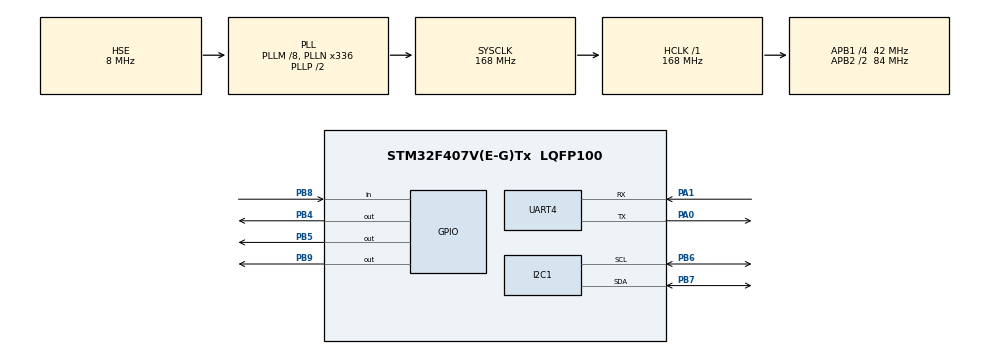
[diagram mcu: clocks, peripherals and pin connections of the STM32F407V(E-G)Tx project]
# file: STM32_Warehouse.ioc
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Dma.Request0=UART4_TX
Dma.UART4_TX.0.Direction=DMA_MEMORY_TO_PERIPH
Dma.UART4_TX.0.FIFOMode=DMA_FIFOMODE_DISABLE
Dma.UART4_TX.0.Instance=DMA1_Stream4
Dma.UART4_TX.0.MemDataAlignment=DMA_MDATAALIGN_BYTE
Dma.UART4_TX.0.MemInc=DMA_MINC_ENABLE
Dma.UART4_TX.0.Mode=DMA_NORMAL
Dma.UART4_TX.0.PeriphDataAlignment=DMA_PDATAALIGN_BYTE
Dma.UART4_TX.0.PeriphInc=DMA_PINC_DISABLE
Dma.UART4_TX.0.Priority=DMA_PRIORITY_HIGH
FREERTOS.Tasks01=defaultTask,0,128,StartDefaultTask,Default,NULL,Dynamic,NULL,NULL;myTask02,0,256,StartTask02,Default,NULL,Dynamic,NULL,NULL;myTask03,-1,128,StartTask03,Default,NULL,Dynamic,NULL,NULL
FREERTOS.configUSE_TIMERS=0
I2C1.I2C_Mode=I2C_Fast
Mcu.Family=STM32F4
Mcu.Name=STM32F407V(E-G)Tx
Mcu.Package=LQFP100
NVIC.DMA1_Stream4_IRQn=true\:5\:0\:false\:false\:true\:true\:false\:true\:true
NVIC.PriorityGroup=NVIC_PRIORITYGROUP_4
NVIC.TIM1_UP_TIM10_IRQn=true\:0\:0\:true\:false\:true\:false\:false\:true\:true
NVIC.TimeBase=TIM1_UP_TIM10_IRQn
NVIC.TimeBaseIP=TIM1
PA0-WKUP.Mode=Asynchronous
PA0-WKUP.Signal=UART4_TX
PA1.Mode=Asynchronous
PA1.Signal=UART4_RX
PA13.Mode=Serial_Wire
PA13.Signal=SYS_JTMS-SWDIO
PA14.Mode=Serial_Wire
PA14.Signal=SYS_JTCK-SWCLK
PB4.GPIO_PuPd=GPIO_PULLDOWN
PB4.PinState=GPIO_PIN_RESET
PB4.Signal=GPIO_Output
PB5.GPIO_PuPd=GPIO_PULLDOWN
PB5.PinState=GPIO_PIN_RESET
PB5.Signal=GPIO_Output
PB6.Mode=I2C
PB6.Signal=I2C1_SCL
PB7.Mode=I2C
PB7.Signal=I2C1_SDA
PB8.GPIO_Mode=GPIO_MODE_INPUT
PB8.GPIO_PuPd=GPIO_PULLDOWN
PB8.Signal=GPIO_Input
PB9.PinState=GPIO_PIN_RESET
PB9.Signal=GPIO_Output
PH0-OSC_IN.Mode=HSE-External-Oscillator
PH0-OSC_IN.Signal=RCC_OSC_IN
PH1-OSC_OUT.Mode=HSE-External-Oscillator
PH1-OSC_OUT.Signal=RCC_OSC_OUT
ProjectManager.HeapSize=0x1000
ProjectManager.StackSize=0x1000
ProjectManager.TargetToolchain=CMake
RCC.48MHZClocksFreq_Value=84000000
RCC.AHBFreq_Value=168000000
RCC.APB1CLKDivider=RCC_HCLK_DIV4
RCC.APB1Freq_Value=42000000
RCC.APB1TimFreq_Value=84000000
RCC.APB2CLKDivider=RCC_HCLK_DIV2
RCC.APB2Freq_Value=84000000
RCC.APB2TimFreq_Value=168000000
RCC.CortexFreq_Value=168000000
RCC.HCLKFreq_Value=168000000
RCC.HSE_VALUE=8000000
RCC.HSI_VALUE=16000000
RCC.LSE_VALUE=32768
RCC.PLLM=8
RCC.PLLN=336
RCC.PLLSourceVirtual=RCC_PLLSOURCE_HSE
RCC.SYSCLKFreq_VALUE=168000000
RCC.SYSCLKSource=RCC_SYSCLKSOURCE_PLLCLK
RCC.VCOOutputFreq_Value=336000000
UART4.VirtualMode=Asynchronous
VP_FREERTOS_VS_CMSIS_V1.Mode=CMSIS_V1
VP_SYS_VS_tim1.Mode=TIM1
board=custom

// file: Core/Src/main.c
/* USER CODE BEGIN Header */
/**
 ******************************************************************************
 * @file           : main.c
 * @brief          : Main program body
 ******************************************************************************
 * @attention
 *
 * Copyright (c) 2024 STMicroelectronics.
 * All rights reserved.
 *
 * This software is licensed under terms that can be found in the LICENSE file
 * in the root directory of this software component.
 * If no LICENSE file comes with this software, it is provided AS-IS.
 *
 ******************************************************************************
 */
/* USER CODE END Header */
#include "main.h"
#include "cmsis_os.h"
#include "dma.h"
#include "i2c.h"
#include "usart.h"
#include "gpio.h"

void SystemClock_Config(void);
void MX_FREERTOS_Init(void);

int main(void)
{

  /* MCU Configuration--------------------------------------------------------*/

  /* Reset of all peripherals, Initializes the Flash interface and the Systick. */
  HAL_Init();

  /* Configure the system clock */
  SystemClock_Config();

  /* Initialize all configured peripherals */
  MX_GPIO_Init();
  MX_DMA_Init();
  MX_I2C1_Init();
  MX_UART4_Init();
  /* USER CODE BEGIN 2 */
  USART1_Init(115200);
  USART2_Init(115200);
  USART3_Init(115200);
  UART4_Init(115200);
  USART6_Init(115200);
  /* USER CODE END 2 */

  /* Call init function for freertos objects (in cmsis_os2.c) */
  MX_FREERTOS_Init();

  /* Start scheduler */
  osKernelStart();

  /* We should never get here as control is now taken by the scheduler */

  /* Infinite loop */
    while (1) {

    }
}

void SystemClock_Config(void)
{
  RCC_OscInitTypeDef RCC_OscInitStruct = {0};
  RCC_ClkInitTypeDef RCC_ClkInitStruct = {0};

  /** Configure the main internal regulator output voltage
  */
  __HAL_RCC_PWR_CLK_ENABLE();
  __HAL_PWR_VOLTAGESCALING_CONFIG(PWR_REGULATOR_VOLTAGE_SCALE1);

  /** Initializes the RCC Oscillators according to the specified parameters
  * in the RCC_OscInitTypeDef structure.
  */
  RCC_OscInitStruct.OscillatorType = RCC_OSCILLATORTYPE_HSE;
  RCC_OscInitStruct.HSEState = RCC_HSE_ON;
  RCC_OscInitStruct.PLL.PLLState = RCC_PLL_ON;
  RCC_OscInitStruct.PLL.PLLSource = RCC_PLLSOURCE_HSE;
  RCC_OscInitStruct.PLL.PLLM = 8;
  RCC_OscInitStruct.PLL.PLLN = 336;
  RCC_OscInitStruct.PLL.PLLP = RCC_PLLP_DIV2;
  RCC_OscInitStruct.PLL.PLLQ = 4;
  if (HAL_RCC_OscConfig(&RCC_OscInitStruct) != HAL_OK)
  {
    Error_Handler();
  }

  /** Initializes the CPU, AHB and APB buses clocks
  */
  RCC_ClkInitStruct.ClockType = RCC_CLOCKTYPE_HCLK|RCC_CLOCKTYPE_SYSCLK
                              |RCC_CLOCKTYPE_PCLK1|RCC_CLOCKTYPE_PCLK2;
  RCC_ClkInitStruct.SYSCLKSource = RCC_SYSCLKSOURCE_PLLCLK;
  RCC_ClkInitStruct.AHBCLKDivider = RCC_SYSCLK_DIV1;
  RCC_ClkInitStruct.APB1CLKDivider = RCC_HCLK_DIV4;
  RCC_ClkInitStruct.APB2CLKDivider = RCC_HCLK_DIV2;

  if (HAL_RCC_ClockConfig(&RCC_ClkInitStruct, FLASH_LATENCY_5) != HAL_OK)
  {
    Error_Handler();
  }
}

void HAL_TIM_PeriodElapsedCallback(TIM_HandleTypeDef *htim)
{
  if (htim->Instance == TIM1) {
    HAL_IncTick();
  }
}

void Error_Handler(void)
{
    __disable_irq();
    while (1) {
    }
}

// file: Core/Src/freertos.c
/* USER CODE BEGIN Header */
/**
  ******************************************************************************
  * File Name          : freertos.c
  * Description        : Code for freertos applications
  ******************************************************************************
  * @attention
  *
  * Copyright (c) 2024 STMicroelectronics.
  * All rights reserved.
  *
  * This software is licensed under terms that can be found in the LICENSE file
  * in the root directory of this software component.
  * If no LICENSE file comes with this software, it is provided AS-IS.
  *
  ******************************************************************************
  */
/* USER CODE END Header */

#include "FreeRTOS.h"
#include "task.h"
#include "main.h"
#include "cmsis_os.h"

/* USER CODE BEGIN Includes */
#include "common_inc.h"
/* USER CODE END Includes */

osThreadId defaultTaskHandle;
osThreadId myTask02Handle;
osThreadId myTask03Handle;

void StartDefaultTask(void const * argument);
void StartTask02(void const * argument);
void StartTask03(void const * argument);

void MX_FREERTOS_Init(void); /* (MISRA C 2004 rule 8.1) */

/* GetIdleTaskMemory prototype (linked to static allocation support) */
void vApplicationGetIdleTaskMemory( StaticTask_t **ppxIdleTaskTCBBuffer, StackType_t **ppxIdleTaskStackBuffer, uint32_t *pulIdleTaskStackSize );

/* USER CODE BEGIN GET_IDLE_TASK_MEMORY */
static StaticTask_t xIdleTaskTCBBuffer;
static StackType_t xIdleStack[configMINIMAL_STACK_SIZE];

void vApplicationGetIdleTaskMemory( StaticTask_t **ppxIdleTaskTCBBuffer, StackType_t **ppxIdleTaskStackBuffer, uint32_t *pulIdleTaskStackSize )
{
  *ppxIdleTaskTCBBuffer = &xIdleTaskTCBBuffer;
  *ppxIdleTaskStackBuffer = &xIdleStack[0];
  *pulIdleTaskStackSize = configMINIMAL_STACK_SIZE;
  /* place for user code */
}
/* USER CODE END GET_IDLE_TASK_MEMORY */

void MX_FREERTOS_Init(void) {

  /* Create the thread(s) */
  /* definition and creation of defaultTask */
  osThreadDef(defaultTask, StartDefaultTask, osPriorityNormal, 0, 128);
  defaultTaskHandle = osThreadCreate(osThread(defaultTask), NULL);

  /* definition and creation of myTask02 */
  osThreadDef(myTask02, StartTask02, osPriorityNormal, 0, 256);
  myTask02Handle = osThreadCreate(osThread(myTask02), NULL);

  /* definition and creation of myTask03 */
  osThreadDef(myTask03, StartTask03, osPriorityBelowNormal, 0, 128);
  myTask03Handle = osThreadCreate(osThread(myTask03), NULL);

}

void StartDefaultTask(void const * argument)
{
  /* USER CODE BEGIN StartDefaultTask */
  rfid_main();
  /* USER CODE END StartDefaultTask */
}

void StartTask02(void const * argument)
{
  /* USER CODE BEGIN StartTask02 */
  /* Infinite loop */
  screen_main();
  /* USER CODE END StartTask02 */
}

void StartTask03(void const * argument)
{
  /* USER CODE BEGIN StartTask03 */
  /* Infinite loop */
  tick();
  /* USER CODE END StartTask03 */
}
